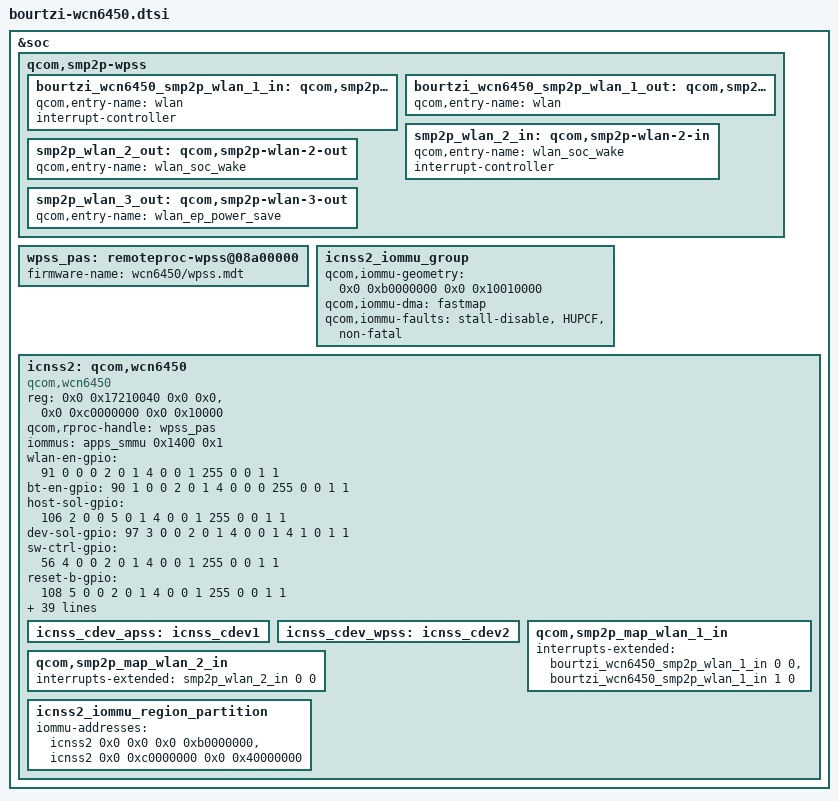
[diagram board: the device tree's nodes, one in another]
// SPDX-License-Identifier: BSD-3-Clause

/*
 * Copyright (c) Qualcomm Technologies, Inc. and/or its subsidiaries.
 */

#include <dt-bindings/interrupt-controller/arm-gic.h>

&soc {
	qcom,smp2p-wpss {
		bourtzi_wcn6450_smp2p_wlan_1_in: qcom,smp2p-wlan-1-in {
			qcom,entry-name = "wlan";
			interrupt-controller;
			#interrupt-cells = <2>;
		};

		bourtzi_wcn6450_smp2p_wlan_1_out: qcom,smp2p-wlan-1-out {
			qcom,entry-name = "wlan";
			#qcom,smem-state-cells = <1>;
		};

		smp2p_wlan_2_in: qcom,smp2p-wlan-2-in {
			qcom,entry-name = "wlan_soc_wake";
			interrupt-controller;
			#interrupt-cells = <2>;
		};

		smp2p_wlan_2_out: qcom,smp2p-wlan-2-out {
			qcom,entry-name = "wlan_soc_wake";
			#qcom,smem-state-cells = <1>;
		};

		smp2p_wlan_3_out: qcom,smp2p-wlan-3-out {
			qcom,entry-name = "wlan_ep_power_save";
			#qcom,smem-state-cells = <1>;
		};
	};

	wpss_pas: remoteproc-wpss@08a00000 {
		firmware-name = "wcn6450/wpss.mdt";
	};

	icnss2_iommu_group: icnss2_iommu_group {
		qcom,iommu-geometry = <0x0 0xb0000000 0x0 0x10010000>;
		qcom,iommu-dma = "fastmap";
		qcom,iommu-faults = "stall-disable", "HUPCF", "non-fatal";
	};

	icnss2: qcom,wcn6450 {
		compatible = "qcom,wcn6450";
		reg = <0x0 0x17210040 0x0 0x0>,
		      <0x0 0xc0000000 0x0 0x10000>;
		reg-names = "msi_addr", "smmu_iova_ipa";
		qcom,rproc-handle = <&wpss_pas>;
		iommus = <&apps_smmu 0x1400 0x1>;

		wlan-en-gpio =  <91  0 0 0 2 0 1 4 0 0 1 255 0 0 1 1>;
		bt-en-gpio =    <90  1 0 0 2 0 1 4 0 0 0 255 0 0 1 1>;
		host-sol-gpio = <106 2 0 0 5 0 1 4 0 0 1 255 0 0 1 1>;
		dev-sol-gpio =  <97  3 0 0 2 0 1 4 0 0 1 4   1 0 1 1>;
		sw-ctrl-gpio =  <56  4 0 0 2 0 1 4 0 0 1 255 0 0 1 1>;
		reset-b-gpio =  <108 5 0 0 2 0 1 4 0 0 1 255 0 0 1 1>;

		interrupts = <GIC_SPI 768 IRQ_TYPE_EDGE_RISING>,
			     <GIC_SPI 769 IRQ_TYPE_EDGE_RISING>,
			     <GIC_SPI 770 IRQ_TYPE_EDGE_RISING>,
			     <GIC_SPI 771 IRQ_TYPE_EDGE_RISING>,
			     <GIC_SPI 772 IRQ_TYPE_EDGE_RISING>,
			     <GIC_SPI 773 IRQ_TYPE_EDGE_RISING>,
			     <GIC_SPI 774 IRQ_TYPE_EDGE_RISING>,
			     <GIC_SPI 775 IRQ_TYPE_EDGE_RISING>,
			     <GIC_SPI 776 IRQ_TYPE_EDGE_RISING>,
			     <GIC_SPI 777 IRQ_TYPE_EDGE_RISING>,
			     <GIC_SPI 778 IRQ_TYPE_EDGE_RISING>,
			     <GIC_SPI 779 IRQ_TYPE_EDGE_RISING>,
			     <GIC_SPI 780 IRQ_TYPE_EDGE_RISING>,
			     <GIC_SPI 781 IRQ_TYPE_EDGE_RISING>;

		qcom,iommu-group = <&icnss2_iommu_group>;
		dma-coherent;
		memory-region = <&icnss2_iommu_region_partition>;
		qcom,fw-prefix;
		qcom,wlan;
		tsens = "sys-therm-3";
		qcom,wlan-msa-fixed-region = <&wlan_msa_mem>;

		vdd-aon-supply = <&S7B>;
		qcom,vdd-aon-config = <1010000 1040000 0 0 1>;
		vdd-1.8-rfa-supply = <&S9B>;
		qcom,vdd-1.8-rfa-config = <1856000 2040000 0 0 0>;
		vdd-1.2-rfa-supply = <&S8B>;
		qcom,vdd-1.2-rfa-config = <1256000 1408000 0 0 0>;
		vdd-cx-supply = <&L4B>;
		qcom,vdd-cx-config = <620000 1050000 28000 0 0>;
		vdd-1.8-io-supply = <&L21B>;
		qcom,vdd-1.8-io-config = <1800000 1800000 0 0 0>;

		qcom,smem-states = <&bourtzi_wcn6450_smp2p_wlan_1_out 0>,
				   <&smp2p_wlan_2_out 0>,
				   <&smp2p_wlan_3_out 0>;
		qcom,smem-state-names = "wlan-smp2p-out",
					"wlan-soc-wake-smp2p-out",
					"wlan-ep-powersave-smp2p-out";

		qcom,qmp = <&aoss_qmp>;

		qcom,vreg_ol_cpr ="L4B0";

		icnss_cdev_apss: icnss_cdev1 {
			#cooling-cells = <2>;
		};

		icnss_cdev_wpss: icnss_cdev2 {
			#cooling-cells = <2>;
		};

		qcom,smp2p_map_wlan_1_in {
			interrupts-extended = <&bourtzi_wcn6450_smp2p_wlan_1_in 0 0>,
					      <&bourtzi_wcn6450_smp2p_wlan_1_in 1 0>;
			interrupt-names = "qcom,smp2p-force-fatal-error",
					  "qcom,smp2p-early-crash-ind";
		};

		qcom,smp2p_map_wlan_2_in {
			interrupts-extended = <&smp2p_wlan_2_in 0 0>;
			interrupt-names = "qcom,smp2p-soc-wake-ack";
		};

		icnss2_iommu_region_partition: icnss2_iommu_region_partition {
			iommu-addresses = <&icnss2 0x0 0x0 0x0 0xb0000000>,
				<&icnss2 0x0 0xc0000000 0x0 0x40000000>;
		};

	};
};
